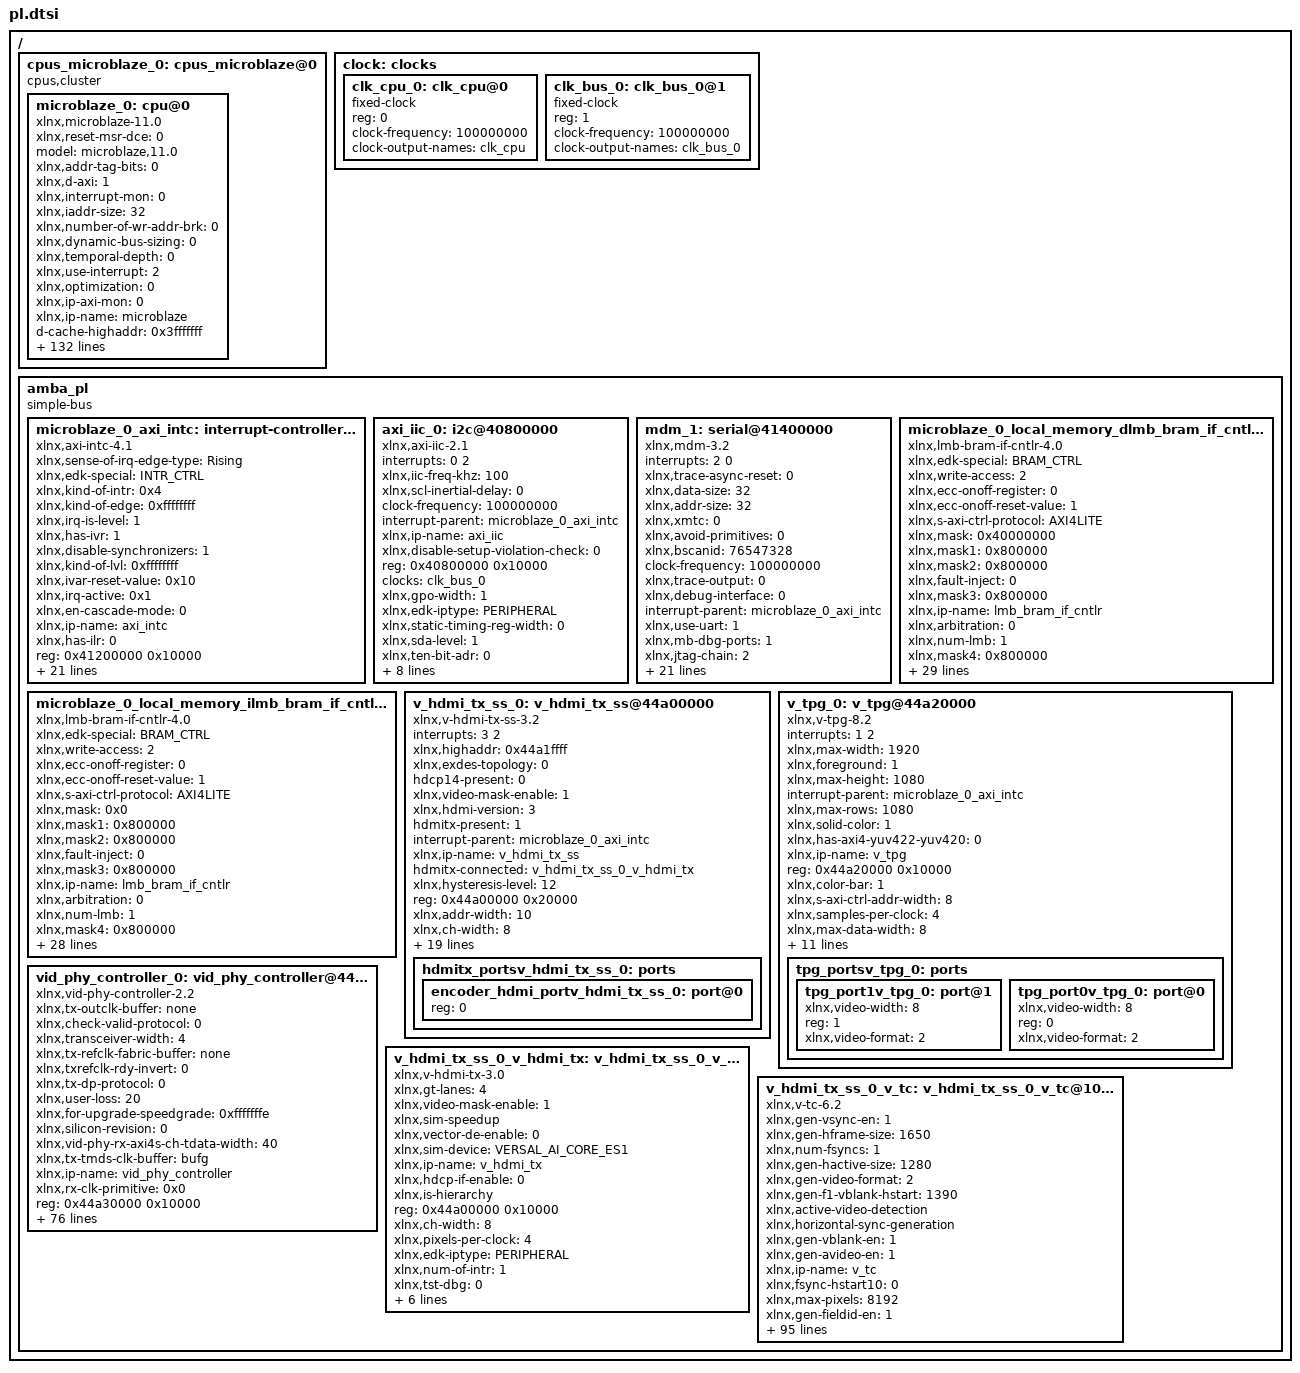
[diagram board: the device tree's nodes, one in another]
/ {
	cpus_microblaze_0: cpus_microblaze@0 {
		#cpu-mask-cells = <1>;
		compatible = "cpus,cluster";
		#address-cells = <1>;
		#size-cells = <0>;
		microblaze_0: cpu@0 {
			xlnx,reset-msr-dce = <0>;
			model = "microblaze,11.0";
			xlnx,addr-tag-bits = <0>;
			xlnx,d-axi = <1>;
			xlnx,interrupt-mon = <0>;
			xlnx,iaddr-size = <32>;
			xlnx,number-of-wr-addr-brk = <0>;
			xlnx,dynamic-bus-sizing = <0>;
			xlnx,temporal-depth = <0>;
			xlnx,use-interrupt = <2>;
			xlnx,optimization = <0>;
			xlnx,ip-axi-mon = <0>;
			xlnx,ip-name = "microblaze";
			d-cache-highaddr = <0x3fffffff>;
			xlnx,dcache-force-tag-lutram = <0>;
			xlnx,pc-width = <32>;
			xlnx,interrupt-is-edge = <0>;
			reg = <0x0>;
			xlnx,async-interrupt = <1>;
			xlnx,use-mmu = <0>;
			xlnx,reset-msr-ee = <0>;
			xlnx,icache-victims = <0>;
			xlnx,use-reorder-instr = <0>;
			xlnx,d-lmb-mon = <0>;
			xlnx,d-lmb-protocol = <0>;
			xlnx,ill-opcode-exception = <0>;
			xlnx,dcache-always-used = <1>;
			xlnx,use-div = <0>;
			xlnx,dc-axi-mon = <0>;
			xlnx,debug-trace-async-reset = <0>;
			xlnx,trace = <0>;
			xlnx,part = "xcau15p-ffvb676-2-e";
			i-cache-baseaddr = <0x0>;
			xlnx,use-config-reset = <0>;
			xlnx,pvr = <0>;
			xlnx,i-lmb-mon = <0>;
			xlnx,dcache-byte-size = <4096>;
			xlnx,fault-tolerant = <0>;
			xlnx,family = "kintexuplus";
			compatible = "xlnx,microblaze-11.0" , "xlnx,microblaze";
			xlnx,data-size = <32>;
			xlnx,mmu-zones = <2>;
			xlnx,debug-trace-size = <8192>;
			xlnx,mmu-privileged-instr = <0>;
			xlnx,enable-discrete-ports = <0>;
			d-cache-line-size = <16>;
			xlnx,d-lmb = <1>;
			xlnx,sco = <0>;
			xlnx,reset-msr-eip = <0>;
			xlnx,debug-interface = <0>;
			clock-frequency = <100000000>;
			xlnx,use-ext-brk = <0>;
			xlnx,daddr-size = <32>;
			xlnx,debug-enabled = <1>;
			xlnx,reset-msr-ice = <0>;
			xlnx,num-sync-ff-dbg-trace-clk = <2>;
			xlnx,i-lmb-protocol = <0>;
			xlnx,endianness = <1>;
			xlnx,fsl-exception = <0>;
			i-cache-line-size = <16>;
			xlnx,use-extended-fsl-instr = <0>;
			xlnx,reset-msr = <0x0>;
			xlnx,dp-axi-mon = <0>;
			device_type = "cpu";
			xlnx,branch-target-cache-size = <0>;
			xlnx,dcache-use-writeback = <0>;
			xlnx,div-zero-exception = <0>;
			xlnx,mmu-tlb-access = <3>;
			bus-handle = <&amba_pl>;
			xlnx,cache-byte-size = <4096>;
			xlnx,pvr-user2 = <0x0>;
			xlnx,opcode-0x0-illegal = <0>;
			xlnx,icache-line-len = <4>;
			xlnx,ecc-use-ce-exception = <0>;
			xlnx,base-vectors = <0x0>;
			xlnx,d-lmb-has-prot = <0>;
			xlnx,edk-special = "microblaze";
			xlnx,use-dcache = <0>;
			xlnx,use-barrel = <1>;
			xlnx,reset-msr-bip = <0>;
			xlnx,allow-dcache-wr = <1>;
			xlnx,debug-external-trace = <0>;
			xlnx,addr-size = <32>;
			xlnx,piaddr-size = <32>;
			i-cache-highaddr = <0x3fffffff>;
			xlnx,num-sync-ff-clk-debug = <2>;
			xlnx,debug-event-counters = <5>;
			xlnx,fpu-exception = <0>;
			xlnx,allow-icache-wr = <1>;
			xlnx,g-use-exceptions = <0>;
			xlnx,i-axi = <0>;
			xlnx,g-template-list = <8>;
			xlnx,icache-streams = <0>;
			xlnx,dcache-line-len = <4>;
			xlnx,num-sync-ff-clk = <2>;
			xlnx,edk-iptype = "PROCESSOR";
			xlnx,use-stack-protection = <0>;
			xlnx,use-hw-mul = <1>;
			xlnx,num-sync-ff-dbg-clk = <1>;
			xlnx,interconnect = <2>;
			xlnx,i-lmb-has-prot = <0>;
			xlnx,debug-latency-counters = <1>;
			i-cache-size = <4096>;
			xlnx,exceptions-in-delay-slots = <1>;
			xlnx,use-fpu = <0>;
			xlnx,reset-msr-ie = <0>;
			xlnx,edge-is-positive = <1>;
			xlnx,use-pcmp-instr = <1>;
			xlnx,use-icache = <0>;
			d-cache-size = <4096>;
			xlnx,memory-ip-list = "microblaze_0_local_memory_ilmb_bram_if_cntlr_memory" , "microblaze_0_local_memory_dlmb_bram_if_cntlr_memory";
			xlnx,async-wakeup = <3>;
			xlnx,use-non-secure = <0>;
			xlnx,dcache-addr-tag = <0>;
			xlnx,number-of-rd-addr-brk = <0>;
			d-cache-baseaddr = <0x0>;
			xlnx,area-optimized = <1>;
			xlnx,avoid-primitives = <0>;
			xlnx,lockstep-slave = <0>;
			xlnx,use-ext-nm-brk = <0>;
			xlnx,instr-size = <32>;
			interrupt-handle = <&microblaze_0_axi_intc>;
			xlnx,icache-always-used = <1>;
			xlnx,i-lmb = <1>;
			xlnx,mmu-dtlb-size = <2>;
			xlnx,lockstep-select = <0>;
			xlnx,lmb-data-size = <32>;
			xlnx,ic-axi-mon = <0>;
			xlnx,enable-conversion = <0>;
			xlnx,num-sync-ff-clk-irq = <1>;
			xlnx,fsl-links = <0>;
			timebase-frequency = <100000000>;
			xlnx,icache-force-tag-lutram = <0>;
			xlnx,dcache-data-width = <0>;
			xlnx,dcache-victims = <0>;
			xlnx,use-branch-target-cache = <0>;
			xlnx,debug-profile-size = <0>;
			xlnx,unaligned-exceptions = <0>;
			xlnx,lockstep-master = <0>;
			xlnx,freq = <100000000>;
			xlnx,number-of-pc-brk = <1>;
			xlnx,mmu-itlb-size = <1>;
			xlnx,imprecise-exceptions = <0>;
			xlnx,use-msr-instr = <1>;
			xlnx,icache-data-width = <0>;
			xlnx,debug-counter-width = <32>;
		};
	};
	clock: clocks {
		#address-cells = <1>;
		#size-cells = <0>;
		clk_cpu_0: clk_cpu@0 {
			compatible = "fixed-clock";
			reg = <0>;
			clock-frequency = <100000000>;
			clock-output-names = "clk_cpu";
			#clock-cells = <0>;
		};
		clk_bus_0: clk_bus_0@1 {
			compatible = "fixed-clock";
			reg = <1>;
			clock-frequency = <100000000>;
			clock-output-names = "clk_bus_0";
			#clock-cells = <0>;
		};
	};
	amba_pl: amba_pl {
		ranges;
		compatible = "simple-bus";
		#address-cells = <1>;
		#size-cells = <1>;
		microblaze_0_axi_intc: interrupt-controller@41200000 {
			#interrupt-cells = <2>;
			xlnx,sense-of-irq-edge-type = "Rising";
			xlnx,edk-special = "INTR_CTRL";
			xlnx,kind-of-intr = <0x4>;
			xlnx,kind-of-edge = <0xffffffff>;
			xlnx,irq-is-level = <1>;
			xlnx,has-ivr = <1>;
			compatible = "xlnx,axi-intc-4.1" , "xlnx,xps-intc-1.00.a";
			xlnx,disable-synchronizers = <1>;
			xlnx,kind-of-lvl = <0xffffffff>;
			xlnx,ivar-reset-value = <0x10>;
			xlnx,irq-active = <0x1>;
			xlnx,en-cascade-mode = <0>;
			xlnx,ip-name = "axi_intc";
			xlnx,has-ilr = <0>;
			reg = <0x41200000 0x10000>;
			xlnx,addr-width = <0x20>;
			xlnx,s-axi-aclk-freq-mhz = <100>;
			xlnx,num-sw-intr = <0>;
			xlnx,irq-connection = <0>;
			xlnx,num-intr-inputs = <0x5>;
			xlnx,has-sie = <1>;
			xlnx,enable-async = <0>;
			xlnx,has-cie = <1>;
			xlnx,num-sync-ff = <2>;
			xlnx,edk-iptype = "PERIPHERAL";
			xlnx,mb-clk-not-connected = <1>;
			xlnx,has-ipr = <1>;
			xlnx,sense-of-irq-level-type = "Active_High";
			xlnx,cascade-master = <0>;
			xlnx,processor-clk-freq-mhz = <100>;
			status = "okay";
			xlnx,is-fast = <0x1>;
			xlnx,has-fast = <1>;
			xlnx,ivar-rst-val = <0x10>;
			interrupt-controller;
			xlnx,async-intr = <0xfffffffe>;
			xlnx,name = "microblaze_0_axi_intc";
		};
		axi_iic_0: i2c@40800000 {
			interrupts = < 0 2 >;
			xlnx,iic-freq-khz = <100>;
			compatible = "xlnx,axi-iic-2.1" , "xlnx,xps-iic-2.00.a";
			xlnx,scl-inertial-delay = <0>;
			clock-frequency = <100000000>;
			interrupt-parent = <&microblaze_0_axi_intc>;
			xlnx,ip-name = "axi_iic";
			xlnx,disable-setup-violation-check = <0>;
			reg = <0x40800000 0x10000>;
			clocks = <&clk_bus_0>;
			xlnx,gpo-width = <1>;
			xlnx,edk-iptype = "PERIPHERAL";
			xlnx,static-timing-reg-width = <0>;
			xlnx,sda-level = <1>;
			status = "okay";
			xlnx,ten-bit-adr = <0>;
			xlnx,default-value = <0x0>;
			interrupt-names = "iic2intc_irpt";
			xlnx,iic-board-interface = "Custom";
			xlnx,timing-reg-width = <32>;
			xlnx,iic-freq = <100000>;
			xlnx,smbus-pmbus-host = <0>;
			xlnx,name = "axi_iic_0";
			xlnx,axi-aclk-freq-mhz = <100>;
			xlnx,sda-inertial-delay = <0>;
		};
		mdm_1: serial@41400000 {
			interrupts = < 2 0 >;
			xlnx,trace-async-reset = <0>;
			compatible = "xlnx,mdm-3.2" , "xlnx,xps-uartlite-1.00.a";
			xlnx,data-size = <32>;
			xlnx,addr-size = <32>;
			xlnx,xmtc = <0>;
			xlnx,avoid-primitives = <0>;
			xlnx,bscanid = <76547328>;
			clock-frequency = <100000000>;
			xlnx,trace-output = <0>;
			xlnx,debug-interface = <0>;
			interrupt-parent = <&microblaze_0_axi_intc>;
			xlnx,use-uart = <1>;
			xlnx,mb-dbg-ports = <1>;
			xlnx,jtag-chain = <2>;
			xlnx,ext-trig-reset-value = <0xf1234>;
			xlnx,trig-in-ports = <1>;
			xlnx,ip-name = "mdm";
			xlnx,brk = <0>;
			xlnx,dbg-reg-access = <0>;
			reg = <0x41400000 0x1000>;
			clocks = <&clk_bus_0>;
			xlnx,use-bscan = <0>;
			xlnx,trace-id = <110>;
			xlnx,lmb-protocol = <0>;
			xlnx,trace-data-width = <32>;
			xlnx,edk-iptype = "PERIPHERAL";
			xlnx,interconnect = <2>;
			xlnx,use-cross-trigger = <0>;
			xlnx,trace-protocol = <1>;
			status = "okay";
			interrupt-names = "Interrupt";
			xlnx,use-config-reset = <0>;
			xlnx,trig-out-ports = <1>;
			xlnx,device = "xcau15p";
			xlnx,dbg-mem-access = <0>;
			xlnx,trace-clk-out-phase = <90>;
			xlnx,name = "mdm_1";
		};
		microblaze_0_local_memory_dlmb_bram_if_cntlr: lmb_bram_if_cntlr@0 {
			xlnx,edk-special = "BRAM_CTRL";
			xlnx,write-access = <2>;
			compatible = "xlnx,lmb-bram-if-cntlr-4.0" , "xlnx,axi-bram-ctrl";
			xlnx,ecc-onoff-register = <0>;
			xlnx,ecc-onoff-reset-value = <1>;
			xlnx,s-axi-ctrl-protocol = "AXI4LITE";
			xlnx,mask = <0x40000000>;
			xlnx,mask1 = <0x800000>;
			xlnx,mask2 = <0x800000>;
			xlnx,fault-inject = <0>;
			xlnx,mask3 = <0x800000>;
			xlnx,ip-name = "lmb_bram_if_cntlr";
			xlnx,arbitration = <0>;
			xlnx,num-lmb = <1>;
			xlnx,mask4 = <0x800000>;
			reg = <0x00000000 0x2000>;
			xlnx,s-axi-ctrl-addr-width = <32>;
			xlnx,mask5 = <0x800000>;
			xlnx,ecc-status-registers = <0>;
			xlnx,prot-cfg = <0xff>;
			xlnx,mask6 = <0x800000>;
			xlnx,lmb-protocol = <0>;
			xlnx,ce-counter-width = <0>;
			xlnx,prot-cfg1 = <0xff>;
			xlnx,mask7 = <0x800000>;
			xlnx,ecc = <0>;
			xlnx,edk-iptype = "PERIPHERAL";
			xlnx,prot-cfg2 = <0xff>;
			xlnx,lmb-dwidth = <32>;
			xlnx,interconnect = <0>;
			xlnx,ce-failing-registers = <0>;
			xlnx,prot-cfg3 = <0xff>;
			xlnx,ue-failing-registers = <0>;
			xlnx,prot-cfg4 = <0xff>;
			xlnx,lmb-has-prot = <0>;
			status = "okay";
			xlnx,data-width = <32>;
			xlnx,prot-cfg5 = <0xff>;
			xlnx,s-axi-ctrl-data-width = <32>;
			xlnx,prot-cfg6 = <0xff>;
			xlnx,bram-awidth = <32>;
			xlnx,prot-cfg7 = <0xff>;
			xlnx,lmb-awidth = <32>;
			xlnx,name = "microblaze_0_local_memory_dlmb_bram_if_cntlr";
		};
		microblaze_0_local_memory_ilmb_bram_if_cntlr: microblaze_0_local_memory_ilmb_bram_if_cntlr@0 {
			xlnx,edk-special = "BRAM_CTRL";
			xlnx,write-access = <2>;
			compatible = "xlnx,lmb-bram-if-cntlr-4.0" , "xlnx,axi-bram-ctrl";
			xlnx,ecc-onoff-register = <0>;
			xlnx,ecc-onoff-reset-value = <1>;
			xlnx,s-axi-ctrl-protocol = "AXI4LITE";
			xlnx,mask = <0x0>;
			xlnx,mask1 = <0x800000>;
			xlnx,mask2 = <0x800000>;
			xlnx,fault-inject = <0>;
			xlnx,mask3 = <0x800000>;
			xlnx,ip-name = "lmb_bram_if_cntlr";
			xlnx,arbitration = <0>;
			xlnx,num-lmb = <1>;
			xlnx,mask4 = <0x800000>;
			reg = <0x00000000 0x2000>;
			xlnx,s-axi-ctrl-addr-width = <32>;
			xlnx,mask5 = <0x800000>;
			xlnx,ecc-status-registers = <0>;
			xlnx,prot-cfg = <0xff>;
			xlnx,mask6 = <0x800000>;
			xlnx,lmb-protocol = <0>;
			xlnx,ce-counter-width = <0>;
			xlnx,prot-cfg1 = <0xff>;
			xlnx,mask7 = <0x800000>;
			xlnx,ecc = <0>;
			xlnx,edk-iptype = "PERIPHERAL";
			xlnx,prot-cfg2 = <0xff>;
			xlnx,lmb-dwidth = <32>;
			xlnx,interconnect = <0>;
			xlnx,ce-failing-registers = <0>;
			xlnx,prot-cfg3 = <0xff>;
			xlnx,ue-failing-registers = <0>;
			xlnx,prot-cfg4 = <0xff>;
			xlnx,lmb-has-prot = <0>;
			status = "okay";
			xlnx,prot-cfg5 = <0xff>;
			xlnx,s-axi-ctrl-data-width = <32>;
			xlnx,prot-cfg6 = <0xff>;
			xlnx,bram-awidth = <32>;
			xlnx,prot-cfg7 = <0xff>;
			xlnx,lmb-awidth = <32>;
			xlnx,name = "microblaze_0_local_memory_ilmb_bram_if_cntlr";
		};
		v_hdmi_tx_ss_0: v_hdmi_tx_ss@44a00000 {
			interrupts = < 3 2 >;
			compatible = "xlnx,v-hdmi-tx-ss-3.2" , "xlnx,v-hdmi-tx-ss-3.1";
			xlnx,highaddr = <0x44a1ffff>;
			xlnx,exdes-topology = <0>;
			hdcp14-present = <0>;
			xlnx,video-mask-enable = <1>;
			xlnx,hdmi-version = <3>;
			hdmitx-present = <1>;
			interrupt-parent = <&microblaze_0_axi_intc>;
			xlnx,ip-name = "v_hdmi_tx_ss";
			hdmitx-connected = <&v_hdmi_tx_ss_0_v_hdmi_tx>;
			xlnx,hysteresis-level = <12>;
			reg = <0x44a00000 0x20000>;
			xlnx,addr-width = <10>;
			xlnx,ch-width = <8>;
			xlnx,exdes-nidru;
			xlnx,exdes-rx-pll-selection = <0>;
			xlnx,vid-interface = <0>;
			xlnx,max-bits-per-component = <8>;
			xlnx,exdes-tx-pll-selection = <6>;
			hdcp22-present = <0>;
			xlnx,add-mark-dbg = <0>;
			xlnx,edk-iptype = "PERIPHERAL";
			vtc-present = <1>;
			xlnx,max-res = <0>;
			xlnx,ddc2-en = <0>;
			status = "okay";
			xlnx,axi-lite-freq-hz = <0x5f5e100>;
			vtc-connected = <&v_hdmi_tx_ss_0_v_tc>;
			xlnx,input-pixels-per-clock = <4>;
			hdcptimer-present = <0>;
			interrupt-names = "irq";
			xlnx,include-yuv420-sup;
			xlnx,include-low-reso-vid;
			xlnx,name = "v_hdmi_tx_ss_0";
			xlnx,exdes-axilite-freq = <100>;
			hdmitx_portsv_hdmi_tx_ss_0: ports {
				#address-cells = <1>;
				#size-cells = <0>;
				encoder_hdmi_portv_hdmi_tx_ss_0: port@0 {
					reg = <0>;
				};
			};
		};
		v_tpg_0: v_tpg@44a20000 {
			interrupts = < 1 2 >;
			compatible = "xlnx,v-tpg-8.2" , "xlnx,v-tpg-8.0";
			xlnx,max-width = <1920>;
			xlnx,foreground = <1>;
			xlnx,max-height = <1080>;
			interrupt-parent = <&microblaze_0_axi_intc>;
			xlnx,max-rows = <1080>;
			xlnx,solid-color = <1>;
			xlnx,has-axi4-yuv422-yuv420 = <0>;
			xlnx,ip-name = "v_tpg";
			reg = <0x44a20000 0x10000>;
			xlnx,color-bar = <1>;
			xlnx,s-axi-ctrl-addr-width = <8>;
			xlnx,samples-per-clock = <4>;
			xlnx,max-data-width = <8>;
			xlnx,has-axi4s-slave = <0>;
			xlnx,ppc = <4>;
			xlnx,max-cols = <1920>;
			xlnx,edk-iptype = "PERIPHERAL";
			status = "okay";
			xlnx,zone-plate = <1>;
			xlnx,num-video-components = <3>;
			interrupt-names = "interrupt";
			xlnx,ramp = <1>;
			xlnx,color-sweep = <1>;
			xlnx,s-axi-ctrl-data-width = <32>;
			xlnx,display-port = <1>;
			xlnx,name = "v_tpg_0";
			tpg_portsv_tpg_0: ports {
				#address-cells = <1>;
				#size-cells = <0>;
				tpg_port1v_tpg_0: port@1 {
					xlnx,video-width = <8>;
					reg = <1>;
					xlnx,video-format = <2>;
				};
				tpg_port0v_tpg_0: port@0 {
					xlnx,video-width = <8>;
					reg = <0>;
					xlnx,video-format = <2>;
				};
			};
		};
		vid_phy_controller_0: vid_phy_controller@44a30000 {
			xlnx,tx-outclk-buffer = "none";
			xlnx,check-valid-protocol = <0>;
			xlnx,transceiver-width = <4>;
			xlnx,tx-refclk-fabric-buffer = "none";
			xlnx,txrefclk-rdy-invert = <0>;
			xlnx,tx-dp-protocol = <0>;
			xlnx,user-loss = <20>;
			xlnx,for-upgrade-speedgrade = <0xfffffffe>;
			xlnx,silicon-revision = <0>;
			xlnx,vid-phy-rx-axi4s-ch-tdata-width = <40>;
			xlnx,tx-tmds-clk-buffer = "bufg";
			xlnx,ip-name = "vid_phy_controller";
			xlnx,rx-clk-primitive = <0x0>;
			reg = <0x44a30000 0x10000>;
			xlnx,drpclk-freq = <0x5f5e100>;
			xlnx,vid-phy-status-sb-rx-tdata-width = <1>;
			xlnx,hdio-rx = <0>;
			xlnx,supportlevel = <1>;
			xlnx,check-pll-selection = <0>;
			xlnx,sub-core-name = "hdmi_tx_bd_vid_phy_controller_0_0_gtwrapper";
			xlnx,vid-phy-axi4lite-addr-width = <10>;
			interrupt-names = "irq";
			xlnx,rx-outclk-buffer = "none";
			xlnx,vid-phy-control-sb-tx-tdata-width = <1>;
			compatible = "xlnx,vid-phy-controller-2.2" , "xlnx,vid-phy-controller-2.1";
			xlnx,rx-max-gt-line-rate = <0x5aa320>;
			xlnx,tx-sb-ports;
			xlnx,for-upgrade-architecture = "kintexuplus";
			xlnx,hdmi-fast-switch = <1>;
			xlnx,rx-video-clk-buffer = "bufg";
			xlnx,channel-enable = "X0Y8 , X0Y9 , X0Y10";
			interrupt-parent = <&microblaze_0_axi_intc>;
			xlnx,transceiver = "GTHE4";
			xlnx,nidru-refclk-sel = <0>;
			xlnx,rx-gt-line-rate = <0x5aa320>;
			xlnx,vid-phy-tx-axi4s-ch-int-tdata-width = <40>;
			xlnx,dru-refclk-fabric-buffer = "none";
			xlnx,err-irq-en = <0>;
			xlnx,vid-phy-rx-axi4s-ch-tuser-width = <1>;
			xlnx,tx-protocol = <1>;
			xlnx,vid-phy-status-sb-tx-tdata-width = <8>;
			xlnx,hdio-tx = <0>;
			status = "okay";
			xlnx,input-pixels-per-clock = <4>;
			xlnx,axi4lite-enable;
			xlnx,axi-aclk-freq-mhz = <0x5f5e100>;
			xlnx,name = "vid_phy_controller_0";
			xlnx,dru-gain-g1-p = <16>;
			interrupts = < 4 2 >;
			xlnx,rx-tdata-width = <40>;
			xlnx,tx-pll-selection = <6>;
			xlnx,vid-phy-tx-axi4s-ch-tdata-width = <40>;
			xlnx,use-oddr-for-tmds-clkout;
			xlnx,for-upgrade-maxoptvol = <0xd5de0>;
			xlnx,edk-iptype = "PERIPHERAL";
			xlnx,speedgrade = <0xfffffffe>;
			xlnx,for-upgrade-package = "ffvb676";
			xlnx,int-hdmi-ver-cmptble = <3>;
			xlnx,int-width = <0>;
			xlnx,rx-sb-ports;
			xlnx,tx-gt-ref-clock-freq = <297>;
			xlnx,tx-buffer-bypass = <1>;
			xlnx,nidru = <0>;
			xlnx,rx-dp-protocol = <0>;
			xlnx,rx-pll-selection = <0>;
			xlnx,tx-tdata-width = <40>;
			xlnx,transceiver-type = <5>;
			xlnx,tx-max-gt-line-rate = <0x5aa320>;
			xlnx,rx-tmds-clk-buffer = "bufg";
			xlnx,vid-phy-rx-axi4s-ch-int-tdata-width = <40>;
			xlnx,vid-phy-axi4lite-data-width = <32>;
			xlnx,tx-video-clk-buffer = "bufg";
			xlnx,for-upgrade-refvol = <0xcf850>;
			xlnx,rx-refclk-sel = <1>;
			xlnx,use-gt-ch4-hdmi = <0>;
			xlnx,for-upgrade-part = "xcau15p-ffvb676-2-e";
			xlnx,tx-refclk-sel = <0>;
			xlnx,for-upgrade-device = "xcau15p";
			xlnx,rx-protocol = <3>;
			xlnx,tx-clk-primitive = <0x0>;
			xlnx,tx-gt-line-rate = <0x5aa320>;
			xlnx,channel-site = "X0Y8";
			xlnx,dru-gain-g1 = <9>;
			xlnx,vid-phy-tx-axi4s-ch-tuser-width = <1>;
			xlnx,dru-gain-g2 = <4>;
			xlnx,rx-no-of-channels = <3>;
			xlnx,rx-gt-ref-clock-freq = <297>;
			xlnx,vid-phy-control-sb-rx-tdata-width = <1>;
			xlnx,device = "xcau15p";
			xlnx,tx-no-of-channels = <3>;
			xlnx,component-name = "hdmi_tx_bd_vid_phy_controller_0_0";
		};
		v_hdmi_tx_ss_0_v_hdmi_tx: v_hdmi_tx_ss_0_v_hdmi_tx@0 {
			compatible = "xlnx,v-hdmi-tx-3.0";
			xlnx,gt-lanes = <4>;
			xlnx,video-mask-enable = <1>;
			xlnx,sim-speedup;
			xlnx,vector-de-enable = <0>;
			xlnx,sim-device = "VERSAL_AI_CORE_ES1";
			xlnx,ip-name = "v_hdmi_tx";
			xlnx,hdcp-if-enable = <0>;
			xlnx,is-hierarchy;
			reg = <0x44a00000 0x10000>;
			xlnx,ch-width = <8>;
			xlnx,pixels-per-clock = <4>;
			xlnx,edk-iptype = "PERIPHERAL";
			xlnx,num-of-intr = <1>;
			xlnx,tst-dbg = <0>;
			xlnx,ddc2-en = <0>;
			xlnx,sim-device-en = <0>;
			status = "okay";
			xlnx,bits-per-component = <8>;
			xlnx,is-versal = <0>;
			xlnx,axi-lite-freq-hz = <0x5f5e100>;
			xlnx,name = "v_hdmi_tx_ss_0_v_hdmi_tx";
		};
		v_hdmi_tx_ss_0_v_tc: v_hdmi_tx_ss_0_v_tc@10000 {
			xlnx,gen-vsync-en = <1>;
			xlnx,gen-hframe-size = <1650>;
			xlnx,num-fsyncs = <1>;
			xlnx,gen-hactive-size = <1280>;
			xlnx,gen-video-format = <2>;
			xlnx,gen-f1-vblank-hstart = <1390>;
			xlnx,active-video-detection;
			xlnx,horizontal-sync-generation;
			xlnx,gen-vblank-en = <1>;
			xlnx,gen-avideo-en = <1>;
			xlnx,ip-name = "v_tc";
			xlnx,fsync-hstart10 = <0>;
			xlnx,max-pixels = <8192>;
			xlnx,gen-fieldid-en = <1>;
			reg = <0x44a10000 0x10000>;
			xlnx,det-vblank-en = <1>;
			xlnx,fsync-hstart11 = <0>;
			xlnx,fsync-hstart12 = <0>;
			xlnx,pixels-per-clock = <0x4>;
			xlnx,gen-interlaced = <0>;
			xlnx,det-avideo-en = <1>;
			xlnx,fsync-hstart13 = <0>;
			xlnx,fsync-hstart14 = <0>;
			xlnx,gen-f0-vblank-hend = <1390>;
			xlnx,fsync-hstart15 = <0>;
			xlnx,det-hsync-en = <1>;
			xlnx,enable-generation;
			xlnx,gen-avideo-polarity = <1>;
			xlnx,max-lines-per-frame = <4096>;
			xlnx,has-axi4-lite = <1>;
			compatible = "xlnx,v-tc-6.2" , "xlnx,bridge-v-tc-6.1";
			xlnx,max-clocks-per-line = <8192>;
			xlnx,gen-f0-vframe-size = <750>;
			xlnx,gen-f0-vblank-hstart = <1390>;
			xlnx,max-lines = <4096>;
			xlnx,gen-f0-vsync-vstart = <724>;
			xlnx,horizontal-blank-generation;
			xlnx,gen-hsync-end = <1430>;
			xlnx,gen-f0-vsync-hstart = <1390>;
			xlnx,gen-f1-vsync-hend = <1390>;
			xlnx,vertical-blank-detection;
			xlnx,gen-vsync-polarity = <1>;
			xlnx,fsync-vstart0 = <0>;
			xlnx,gen-hsync-polarity = <1>;
			xlnx,fsync-vstart1 = <0>;
			status = "okay";
			xlnx,fsync-vstart2 = <0>;
			xlnx,gen-hsync-start = <1390>;
			xlnx,gen-f0-vsync-vend = <729>;
			xlnx,fsync-vstart3 = <0>;
			xlnx,vertical-sync-detection;
			xlnx,frame-syncs = <1>;
			xlnx,fsync-vstart4 = <0>;
			xlnx,gen-vactive-size = <720>;
			xlnx,name = "v_hdmi_tx_ss_0_v_tc";
			xlnx,fsync-vstart5 = <0>;
			xlnx,gen-achroma-en = <0>;
			xlnx,fsync-vstart6 = <0>;
			xlnx,det-fieldid-en = <0>;
			xlnx,fsync-vstart7 = <0>;
			xlnx,gen-hsync-en = <1>;
			xlnx,fsync-vstart8 = <0>;
			xlnx,fsync-vstart10 = <0>;
			xlnx,fsync-vstart9 = <0>;
			xlnx,fsync-vstart11 = <0>;
			xlnx,arbitrary-res-en = /bits/ 8 <0x0>;
			xlnx,fsync-vstart12 = <0>;
			xlnx,is-hierarchy;
			xlnx,fsync-vstart13 = <0>;
			xlnx,fsync-vstart14 = <0>;
			xlnx,fsync-vstart15 = <0>;
			xlnx,gen-cparity = <0>;
			xlnx,edk-iptype = "PERIPHERAL";
			xlnx,vertical-sync-generation;
			xlnx,gen-f1-vblank-hend = <1390>;
			xlnx,det-vsync-en = <1>;
			xlnx,gen-vblank-polarity = <1>;
			xlnx,fsync-hstart0 = <0>;
			xlnx,interlace-en = <1>;
			xlnx,gen-auto-switch = <0>;
			xlnx,fsync-hstart1 = <0>;
			xlnx,fsync-hstart2 = <0>;
			xlnx,active-video-generation;
			xlnx,fsync-hstart3 = <0>;
			xlnx,fsync-hstart4 = <0>;
			xlnx,horizontal-blank-detection;
			xlnx,fsync-hstart5 = <0>;
			xlnx,gen-f1-vframe-size = <750>;
			xlnx,fsync-hstart6 = <0>;
			xlnx,fsync-hstart7 = <0>;
			xlnx,fsync-hstart8 = <0>;
			xlnx,gen-hblank-en = <1>;
			xlnx,fsync-hstart9 = <0>;
			xlnx,horizontal-sync-detection;
			xlnx,gen-f1-vsync-vend = <729>;
			xlnx,detect-en = <0>;
			xlnx,det-hblank-en = <1>;
			xlnx,vid-ppc = <4>;
			xlnx,has-intc-if = <0>;
			xlnx,generate-en = <1>;
			xlnx,gen-achroma-polarity = <1>;
			xlnx,sync-en = <0>;
			xlnx,det-achroma-en = <0>;
			xlnx,generator;
			xlnx,gen-f1-vsync-vstart = <724>;
			xlnx,vertical-blank-generation;
			xlnx,gen-hblank-polarity = <1>;
			xlnx,video-mode = "720p";
			xlnx,gen-fieldid-polarity = <1>;
			xlnx,gen-f1-vsync-hstart = <1390>;
			xlnx,gen-f0-vsync-hend = <1390>;
		};
	};
};
